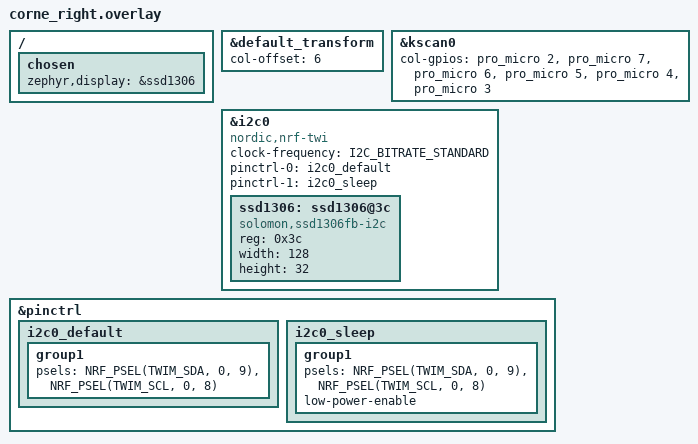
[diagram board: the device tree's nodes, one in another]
#include "corne.dtsi"

&default_transform {
    col-offset = <6>;  
};

&kscan0 {
    col-gpios = <&pro_micro 2 GPIO_ACTIVE_HIGH>,
                <&pro_micro 7 GPIO_ACTIVE_HIGH>,
                <&pro_micro 6 GPIO_ACTIVE_HIGH>,
                <&pro_micro 5 GPIO_ACTIVE_HIGH>,
                <&pro_micro 4 GPIO_ACTIVE_HIGH>,
                <&pro_micro 3 GPIO_ACTIVE_HIGH>;
};

/ {
    chosen {
        zephyr,display = &ssd1306;
    };
};

&i2c0 {
    compatible = "nordic,nrf-twi";
    status = "okay";
    clock-frequency = <I2C_BITRATE_STANDARD>;

    pinctrl-0 = <&i2c0_default>;
    pinctrl-1 = <&i2c0_sleep>;
    pinctrl-names = "default", "sleep";

    ssd1306: ssd1306@3c {
        compatible = "solomon,ssd1306fb-i2c";
        reg = <0x3c>;

        width = <128>;
        height = <32>;
    };
};


&pinctrl {
    i2c0_default: i2c0_default {
        group1 {
            psels = <NRF_PSEL(TWIM_SDA, 0, 9)>,
                    <NRF_PSEL(TWIM_SCL, 0, 8)>;
        };
    };

    i2c0_sleep: i2c0_sleep {
        group1 {
            psels = <NRF_PSEL(TWIM_SDA, 0, 9)>,
                    <NRF_PSEL(TWIM_SCL, 0, 8)>;
            low-power-enable;
        };
    };
};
